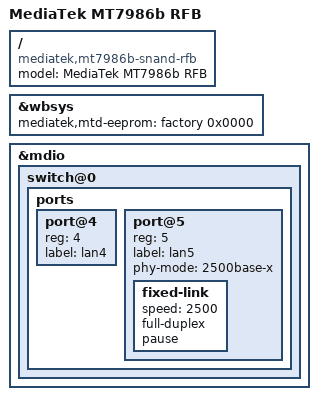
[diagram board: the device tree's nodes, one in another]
/dts-v1/;
#include "mt7986b-rfb.dtsi"
/ {
	model = "MediaTek MT7986b RFB";
	compatible = "mediatek,mt7986b-snand-rfb";
};

&wbsys {
	mediatek,mtd-eeprom = <&factory 0x0000>;
	status = "okay";
};

&mdio {
	switch@0 {
		ports {
			port@4 {
				reg = <4>;
				label = "lan4";
			};

			port@5 {
				reg = <5>;
				label = "lan5";
				phy-mode = "2500base-x";

				fixed-link {
					speed = <2500>;
					full-duplex;
					pause;
				};
			};
		};
	};
};
